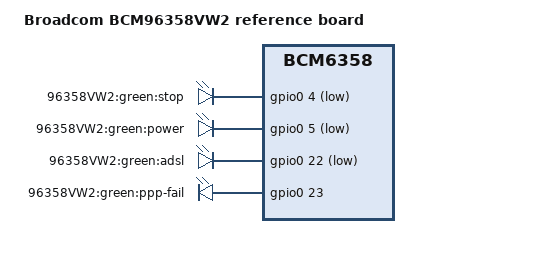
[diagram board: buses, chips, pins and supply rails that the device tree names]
/dts-v1/;

#include "bcm6358.dtsi"

#include <dt-bindings/input/input.h>

/ {
	model = "Broadcom BCM96358VW2 reference board";
	compatible = "brcm,bcm96358vw2", "brcm,bcm6358";

	gpio-leds {
		compatible = "gpio-leds";

		stop_green {
			label = "96358VW2:green:stop";
			gpios = <&gpio0 4 1>;
		};
		power_green {
			label = "96358VW2:green:power";
			gpios = <&gpio0 5 1>;
			default-state = "on";
		};
		adsl_green {
			label = "96358VW2:green:adsl";
			gpios = <&gpio0 22 1>;
		};
		ppp_fail_green {
			label = "96358VW2:green:ppp-fail";
			gpios = <&gpio0 23 0>;
		};
	};
};
